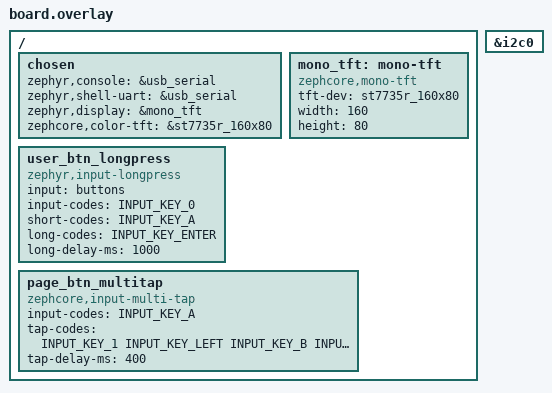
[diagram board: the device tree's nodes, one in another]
/*
 * SPDX-License-Identifier: MIT
 * Heltec Wireless Tracker V2 — ZephCore overlay
 *
 * The full DTS defines: SX1262 (lora0), ST7735R 160x80 TFT, UC6580 GNSS,
 * button, status LED, battery ADC, Vext, FEM power, I2C0, SPI2/3, BLE, WiFi.
 * This overlay adds ZephCore-specific integration on top.
 */

#include <zephyr/dt-bindings/input/input-event-codes.h>

/ {
	chosen {
		/* Native USB serial/JTAG for ZephCore console and CLI. */
		zephyr,console = &usb_serial;
		zephyr,shell-uart = &usb_serial;

		/* Mono-TFT wrapper: presents PIXEL_FORMAT_MONO01 to CFB and converts
		 * each row to RGB565 for the ST7735R colour TFT. */
		zephyr,display = &mono_tft;

		/* Same panel drawn a second way: the colour overlay renderer writes
		 * raw RGB565 straight to the ST7735R, bypassing the mono wrapper.
		 * Identical panel and init sequence to the T096, so the same badges,
		 * coloured text and activity graph apply here. */
		zephcore,color-tft = &st7735r_160x80;
	};

	mono_tft: mono-tft {
		compatible = "zephcore,mono-tft";
		tft-dev = <&st7735r_160x80>;
		width = <160>;
		height = <80>;
	};

	/*
	 * Button chain: long press enters, taps drive the gesture ladder below.
	 *
	 *   1 tap  (400ms wait) → KEY_1    = page next
	 *   2 taps (400ms wait) → KEY_LEFT = page previous
	 *   3 taps (400ms wait) → KEY_B    = LED heartbeat toggle
	 *   4 taps (400ms wait) → KEY_C    = GPS on/off
	 *   5 taps (immediate)  → KEY_E    = flood advert
	 *
	 * This is the T096 variant of the 5-tap ladder — page-prev stays at slot
	 * 2 because this board has a screen.  Screenless boards use KEY_B there
	 * instead, where page-prev would be a no-op.
	 */
	user_btn_longpress {
		compatible = "zephyr,input-longpress";
		input = <&buttons>;
		input-codes = <INPUT_KEY_0>;
		short-codes = <INPUT_KEY_A>;
		long-codes = <INPUT_KEY_ENTER>;
		long-delay-ms = <1000>;
	};

	page_btn_multitap {
		compatible = "zephcore,input-multi-tap";
		input-codes = <INPUT_KEY_A>;
		tap-codes = <INPUT_KEY_1 INPUT_KEY_LEFT INPUT_KEY_B INPUT_KEY_C INPUT_KEY_E>;
		tap-delay-ms = <400>;
	};
};

/* I2C sensors — auto-detected at runtime. Header pins per MeshCore:
 * SDA=GPIO6, SCL=GPIO17. */
&i2c0 {
	#include "../../common/sensors-i2c.dtsi"
};

/*
 * Flash partitions live in partitions.overlay (this dir) so the identical map
 * is fed to both the app and the MCUboot image — see that file and
 * sysbuild/CMakeLists.txt.
 */

/* LittleFS auto-mount — standard /lfs mount point */
#include "../../common/filesystem.dtsi"

/* USB CDC-ACM companion transport when built with boards/common/esp32s3_usb.conf. */
#include "../../common/esp32s3_usb_otg.dtsi"
